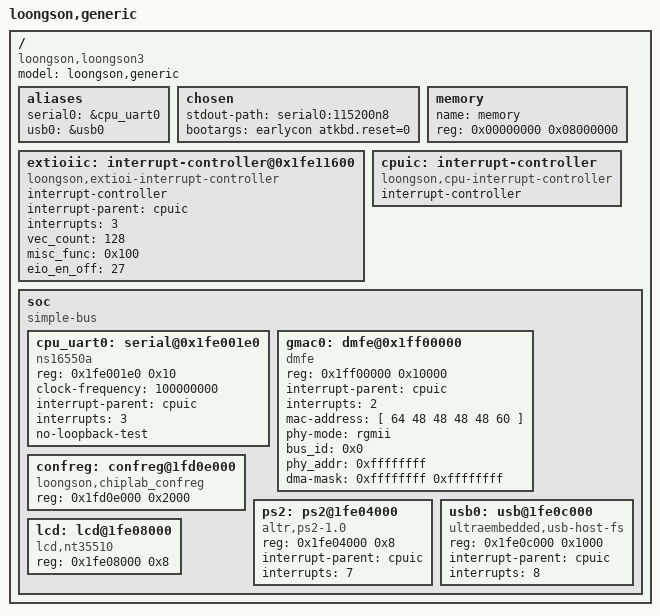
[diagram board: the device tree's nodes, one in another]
// SPDX-License-Identifier: GPL-2.0
/dts-v1/;

/ {
	model = "loongson,generic";
	compatible = "loongson,loongson3";
	#address-cells = <1>;
	#size-cells = <1>;

	aliases {
		serial0 = &cpu_uart0;
		usb0 = &usb0;
	};

	chosen {
		stdout-path = "serial0:115200n8";
		bootargs = "earlycon atkbd.reset=0";
	};

	extioiic: interrupt-controller@0x1fe11600 {
		compatible = "loongson,extioi-interrupt-controller";
		interrupt-controller;
		#interrupt-cells = <1>;
		interrupt-parent = <&cpuic>;
		interrupts = <3>;
		interrupt-names = "cascade";
		vec_count=<128>;
		misc_func=<0x100>;
		eio_en_off=<27>;
	};

	memory {
		name = "memory";
		device_type = "memory";
		reg = <0x00000000  0x08000000>;
	};

	cpuic: interrupt-controller {
		compatible = "loongson,cpu-interrupt-controller";
		interrupt-controller;
		#interrupt-cells = <1>;
	};

	soc {
		compatible = "simple-bus";
		#address-cells = <1>;
		#size-cells = <1>;
		ranges = <0x10000000 0x10000000 0x10000000>;

		cpu_uart0: serial@0x1fe001e0 {
			compatible = "ns16550a";
			reg = <0x1fe001e0  0x10>;
			/* UART input clock:
			 *   实验箱 SoC (loongson):   33 MHz (aclkl/uncore_clk)
			 *   竞赛 SoC  (nscscc-team): 100 MHz (sys_clk)
			 *   根据你的 SoC 改这里 + serial.c 里的 uartclk
			 */
			clock-frequency = <100000000>;
			interrupt-parent = <&cpuic>;
			interrupts = <3>;
			no-loopback-test;
		};

		gmac0: dmfe@0x1ff00000 {
			compatible = "dmfe";
			reg = <0x1ff00000 0x10000>;
			interrupt-parent = <&cpuic>;
			interrupts = <2>;
			interrupt-names = "macirq";
			mac-address = [ 64 48 48 48 48 60 ];/* [>mac 64:48:48:48:48:60 <]*/
			phy-mode = "rgmii";
			bus_id = <0x0>;
			phy_addr = <0xffffffff>;
			dma-mask = <0xffffffff 0xffffffff>;
		};

		confreg: confreg@1fd0e000 {
			compatible = "loongson,chiplab_confreg";
			reg = <0x1fd0e000 0x2000>;
		};

		ps2: ps2@1fe04000 {
			compatible = "altr,ps2-1.0";
			reg = <0x1fe04000 0x8>;
			interrupt-parent = <&cpuic>;
			interrupts = <7>;
		};

		usb0: usb@1fe0c000 {
			compatible = "ultraembedded,usb-host-fs", "ue11-hcd";
			reg = <0x1fe0c000 0x1000>;
			interrupt-parent = <&cpuic>;
			interrupts = <8>;
			status = "okay";
		};

		lcd: lcd@1fe08000 {
			compatible = "lcd,nt35510";
			reg = <0x1fe08000 0x8>;
		};
#if 0
		ahci@0x1fe30000 {
			compatible = "snps,spear-ahci";
			reg = <0x1fe30000 0x10000>;
			interrupt-parent = <&cpuic>;
			interrupts = <4>;
			dma-mask = <0x0 0xffffffff>;
	    	};

		nand@0x1fe78000 {
			#address-cells = <1>;
			#size-cells = <1>;
			compatible = "ls1a-nand";
			reg = <0x1fe78000 0x4000
			 0x1fd01160 0x0>;
			interrupt-parent = <&cpuic>;
			interrupts = <4>;
			interrupt-names = "nand_irq";

			number-of-parts = <0x2>;
			partition@0 {
				label = "kernel_partition";
				reg = <0x0000000 0x01400000>;
			};

			partition@0x01400000 {
				label = "os_partition";
				reg = <0x01400000 0x0>;
			};
		};
#endif
	};
};
